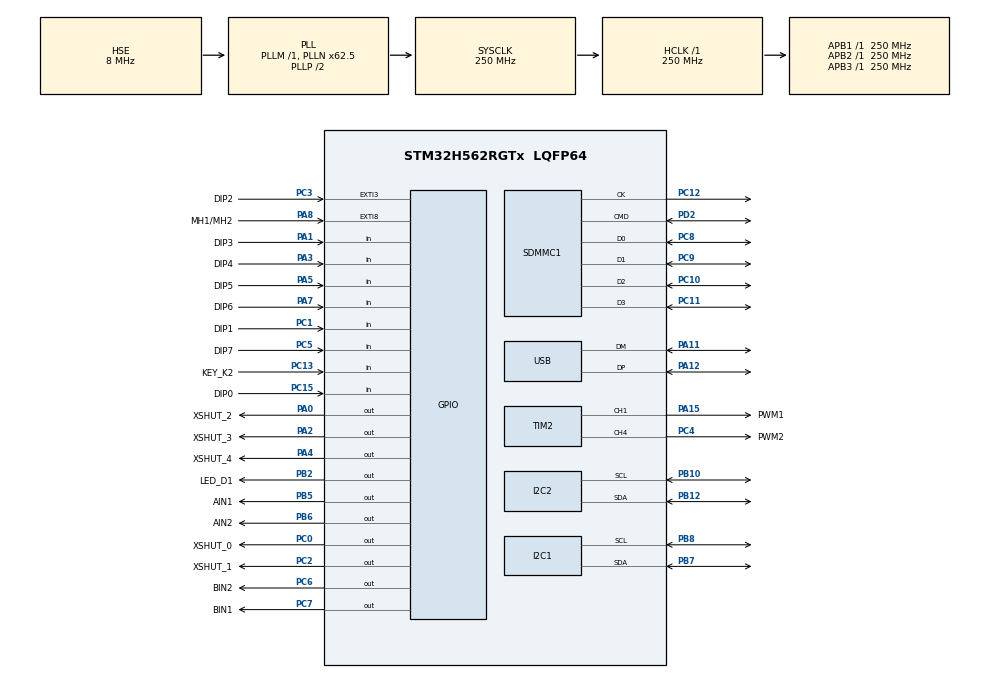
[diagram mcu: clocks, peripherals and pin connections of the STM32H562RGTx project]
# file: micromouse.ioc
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BOOTPATH.BootPathName=LEGACY
BOOTPATH.UserSelectedBootPath=LEGACY
CORTEX_M33_NS.userName=CORTEX_M33
I2C1.Timing=0x60808CD3
I2C2.Timing=0x60808CD3
Mcu.Family=STM32H5
Mcu.Name=STM32H562RGTx
Mcu.Package=LQFP64
NVIC.PriorityGroup=NVIC_PRIORITYGROUP_4
PA0.GPIO_Label=XSHUT_2
PA0.Signal=GPIO_Output
PA1.GPIO_Label=DIP3
PA1.Signal=GPIO_Input
PA11.Mode=Device
PA11.Signal=USB_DM
PA12.Mode=Device
PA12.Signal=USB_DP
PA13(JTMS/SWDIO).Mode=Trace_Asynchronous_SW
PA13(JTMS/SWDIO).Signal=DEBUG_JTMS-SWDIO
PA14(JTCK/SWCLK).Mode=Trace_Asynchronous_SW
PA14(JTCK/SWCLK).Signal=DEBUG_JTCK-SWCLK
PA15(JTDI).GPIO_Label=PWM1
PA15(JTDI).Signal=S_TIM2_CH1
PA2.GPIO_Label=XSHUT_3
PA2.Signal=GPIO_Output
PA3.GPIO_Label=DIP4
PA3.Signal=GPIO_Input
PA4.GPIO_Label=XSHUT_4
PA4.Signal=GPIO_Output
PA5.GPIO_Label=DIP5
PA5.Signal=GPIO_Input
PA7.GPIO_Label=DIP6
PA7.Signal=GPIO_Input
PA8.GPIO_Label=MH1/MH2
PA8.Signal=GPXTI8
PB10.Mode=I2C
PB10.Signal=I2C2_SCL
PB12.Mode=I2C
PB12.Signal=I2C2_SDA
PB2.GPIO_Label=LED_D1
PB2.Signal=GPIO_Output
PB3(JTDO/TRACESWO).Mode=Trace_Asynchronous_SW
PB3(JTDO/TRACESWO).Signal=DEBUG_JTDO-SWO
PB5.GPIO_Label=AIN1
PB5.Signal=GPIO_Output
PB6.GPIO_Label=AIN2
PB6.Signal=GPIO_Output
PB7.Mode=I2C
PB7.Signal=I2C1_SDA
PB8.Mode=I2C
PB8.Signal=I2C1_SCL
PC0.GPIO_Label=XSHUT_0
PC0.Signal=GPIO_Output
PC1.GPIO_Label=DIP1
PC1.Signal=GPIO_Input
PC10.Mode=SD_4_bits_Wide_bus
PC10.Signal=SDMMC1_D2
PC11.Mode=SD_4_bits_Wide_bus
PC11.Signal=SDMMC1_D3
PC12.Mode=SD_4_bits_Wide_bus
PC12.Signal=SDMMC1_CK
PC13.GPIO_Label=KEY_K2
PC13.Signal=GPIO_Input
PC15-OSC32_OUT(OSC32_OUT).GPIO_Label=DIP0
PC15-OSC32_OUT(OSC32_OUT).Signal=GPIO_Input
PC2.GPIO_Label=XSHUT_1
PC2.Signal=GPIO_Output
PC3.GPIO_Label=DIP2
PC3.Signal=GPXTI3
PC4.GPIO_Label=PWM2
PC4.Signal=S_TIM2_CH4
PC5.GPIO_Label=DIP7
PC5.Signal=GPIO_Input
PC6.GPIO_Label=BIN2
PC6.Signal=GPIO_Output
PC7.GPIO_Label=BIN1
PC7.Signal=GPIO_Output
PC8.Mode=SD_4_bits_Wide_bus
PC8.Signal=SDMMC1_D0
PC9.Mode=SD_4_bits_Wide_bus
PC9.Signal=SDMMC1_D1
PD2.Mode=SD_4_bits_Wide_bus
PD2.Signal=SDMMC1_CMD
PH0-OSC_IN(PH0).Mode=HSE-External-Oscillator
PH0-OSC_IN(PH0).Signal=RCC_OSC_IN
PH1-OSC_OUT(PH1).Mode=HSE-External-Oscillator
PH1-OSC_OUT(PH1).Signal=RCC_OSC_OUT
ProjectManager.HeapSize=0x200
ProjectManager.StackSize=0x400
ProjectManager.TargetToolchain=STM32CubeIDE
RCC.ADCFreq_Value=250000000
RCC.AHBFreq_Value=250000000
RCC.APB1Freq_Value=250000000
RCC.APB1TimFreq_Value=250000000
RCC.APB2Freq_Value=250000000
RCC.APB2TimFreq_Value=250000000
RCC.APB3Freq_Value=250000000
RCC.CSI_VALUE=4000000
RCC.CortexFreq_Value=250000000
RCC.EPOD_VALUE=8000000
RCC.HCLKFreq_Value=250000000
RCC.HSE_VALUE=8000000
RCC.HSI48_VALUE=48000000
RCC.HSI_VALUE=64000000
RCC.LSE_VALUE=32768
RCC.LSIRC_VALUE=32000
RCC.PLLFRACN=4096
RCC.PLLN=62
RCC.PLLSourceVirtual=RCC_PLL1_SOURCE_HSE
RCC.SYSCLKFreq_VALUE=250000000
RCC.SYSCLKSource=RCC_SYSCLKSOURCE_PLLCLK
RCC.USBFreq_Value=48000000
RCC.VCOOutputFreq_Value=500000000
SH.S_TIM2_CH1.0=TIM2_CH1,PWM Generation1 CH1
SH.S_TIM2_CH4.0=TIM2_CH4,PWM Generation4 CH4
TIM2.Channel-PWM\ Generation1\ CH1=TIM_CHANNEL_1
TIM2.Channel-PWM\ Generation4\ CH4=TIM_CHANNEL_4
USB.VirtualMode=Device_Only
VP_BOOTPATH_VS_BOOTPATH.Mode=BP_Activate
VP_CORTEX_M33_NS_VS_Hclk.Mode=Hclk_Mode
VP_ICACHE_VS_ICACHE.Mode=DirectMappedCache
VP_MEMORYMAP_VS_MEMORYMAP.Mode=CurAppReg
VP_PWR_VS_LPOM.Mode=PowerOptimisation
VP_PWR_VS_SECSignals.Mode=Security/Privilege
VP_TIM2_VS_ClockSourceINT.Mode=Internal
board=custom

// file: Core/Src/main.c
/* USER CODE BEGIN Header */
/**
  ******************************************************************************
  * @file           : main.c
  * @brief          : Main program body
  ******************************************************************************
  * @attention
  *
  * Copyright (c) 2025 STMicroelectronics.
  * All rights reserved.
  *
  * This software is licensed under terms that can be found in the LICENSE file
  * in the root directory of this software component.
  * If no LICENSE file comes with this software, it is provided AS-IS.
  *
  ******************************************************************************
  */
/* USER CODE END Header */
#include "main.h"

/* USER CODE BEGIN Includes */
#include <stdio.h>
#include "solver.h"
//#include "API.h"
/* USER CODE END Includes */

I2C_HandleTypeDef hi2c1;
I2C_HandleTypeDef hi2c2;

SD_HandleTypeDef hsd1;

TIM_HandleTypeDef htim2;

PCD_HandleTypeDef hpcd_USB_DRD_FS;

void SystemClock_Config(void);
static void MX_GPIO_Init(void);
static void MX_ICACHE_Init(void);
static void MX_TIM2_Init(void);
static void MX_I2C1_Init(void);
static void MX_I2C2_Init(void);
static void MX_SDMMC1_SD_Init(void);
static void MX_USB_PCD_Init(void);

int main(int argc, char* argv[])
{

  /* MCU Configuration--------------------------------------------------------*/

  /* Reset of all peripherals, Initializes the Flash interface and the Systick. */
  HAL_Init();

  /* Configure the system clock */
  SystemClock_Config();

  /* Initialize all configured peripherals */
  MX_GPIO_Init();
  MX_ICACHE_Init();
  MX_TIM2_Init();
  MX_I2C1_Init();
  MX_I2C2_Init();
  MX_SDMMC1_SD_Init();
  MX_USB_PCD_Init();
  /* USER CODE BEGIN 2 */
  //debug_log("Running...");
  generateInitialWalls();
  /* USER CODE END 2 */

  /* Infinite loop */
  while (1)
  {
	  Action nextMove = solver();
  }
}

void SystemClock_Config(void)
{
  RCC_OscInitTypeDef RCC_OscInitStruct = {0};
  RCC_ClkInitTypeDef RCC_ClkInitStruct = {0};

  /** Configure the main internal regulator output voltage
  */
  __HAL_PWR_VOLTAGESCALING_CONFIG(PWR_REGULATOR_VOLTAGE_SCALE0);

  while(!__HAL_PWR_GET_FLAG(PWR_FLAG_VOSRDY)) {}

  /** Initializes the RCC Oscillators according to the specified parameters
  * in the RCC_OscInitTypeDef structure.
  */
  RCC_OscInitStruct.OscillatorType = RCC_OSCILLATORTYPE_HSI48|RCC_OSCILLATORTYPE_HSE;
  RCC_OscInitStruct.HSEState = RCC_HSE_ON;
  RCC_OscInitStruct.HSI48State = RCC_HSI48_ON;
  RCC_OscInitStruct.PLL.PLLState = RCC_PLL_ON;
  RCC_OscInitStruct.PLL.PLLSource = RCC_PLL1_SOURCE_HSE;
  RCC_OscInitStruct.PLL.PLLM = 1;
  RCC_OscInitStruct.PLL.PLLN = 62;
  RCC_OscInitStruct.PLL.PLLP = 2;
  RCC_OscInitStruct.PLL.PLLQ = 2;
  RCC_OscInitStruct.PLL.PLLR = 2;
  RCC_OscInitStruct.PLL.PLLRGE = RCC_PLL1_VCIRANGE_3;
  RCC_OscInitStruct.PLL.PLLVCOSEL = RCC_PLL1_VCORANGE_WIDE;
  RCC_OscInitStruct.PLL.PLLFRACN = 4096;
  if (HAL_RCC_OscConfig(&RCC_OscInitStruct) != HAL_OK)
  {
    Error_Handler();
  }

  /** Initializes the CPU, AHB and APB buses clocks
  */
  RCC_ClkInitStruct.ClockType = RCC_CLOCKTYPE_HCLK|RCC_CLOCKTYPE_SYSCLK
                              |RCC_CLOCKTYPE_PCLK1|RCC_CLOCKTYPE_PCLK2
                              |RCC_CLOCKTYPE_PCLK3;
  RCC_ClkInitStruct.SYSCLKSource = RCC_SYSCLKSOURCE_PLLCLK;
  RCC_ClkInitStruct.AHBCLKDivider = RCC_SYSCLK_DIV1;
  RCC_ClkInitStruct.APB1CLKDivider = RCC_HCLK_DIV1;
  RCC_ClkInitStruct.APB2CLKDivider = RCC_HCLK_DIV1;
  RCC_ClkInitStruct.APB3CLKDivider = RCC_HCLK_DIV1;

  if (HAL_RCC_ClockConfig(&RCC_ClkInitStruct, FLASH_LATENCY_5) != HAL_OK)
  {
    Error_Handler();
  }

  /** Configure the programming delay
  */
  __HAL_FLASH_SET_PROGRAM_DELAY(FLASH_PROGRAMMING_DELAY_2);
}

static void MX_I2C1_Init(void)
{

  hi2c1.Instance = I2C1;
  hi2c1.Init.Timing = 0x60808CD3;
  hi2c1.Init.OwnAddress1 = 0;
  hi2c1.Init.AddressingMode = I2C_ADDRESSINGMODE_7BIT;
  hi2c1.Init.DualAddressMode = I2C_DUALADDRESS_DISABLE;
  hi2c1.Init.OwnAddress2 = 0;
  hi2c1.Init.OwnAddress2Masks = I2C_OA2_NOMASK;
  hi2c1.Init.GeneralCallMode = I2C_GENERALCALL_DISABLE;
  hi2c1.Init.NoStretchMode = I2C_NOSTRETCH_DISABLE;
  if (HAL_I2C_Init(&hi2c1) != HAL_OK)
  {
    Error_Handler();
  }

  /** Configure Analogue filter
  */
  if (HAL_I2CEx_ConfigAnalogFilter(&hi2c1, I2C_ANALOGFILTER_ENABLE) != HAL_OK)
  {
    Error_Handler();
  }

  /** Configure Digital filter
  */
  if (HAL_I2CEx_ConfigDigitalFilter(&hi2c1, 0) != HAL_OK)
  {
    Error_Handler();
  }

}

static void MX_I2C2_Init(void)
{

  hi2c2.Instance = I2C2;
  hi2c2.Init.Timing = 0x60808CD3;
  hi2c2.Init.OwnAddress1 = 0;
  hi2c2.Init.AddressingMode = I2C_ADDRESSINGMODE_7BIT;
  hi2c2.Init.DualAddressMode = I2C_DUALADDRESS_DISABLE;
  hi2c2.Init.OwnAddress2 = 0;
  hi2c2.Init.OwnAddress2Masks = I2C_OA2_NOMASK;
  hi2c2.Init.GeneralCallMode = I2C_GENERALCALL_DISABLE;
  hi2c2.Init.NoStretchMode = I2C_NOSTRETCH_DISABLE;
  if (HAL_I2C_Init(&hi2c2) != HAL_OK)
  {
    Error_Handler();
  }

  /** Configure Analogue filter
  */
  if (HAL_I2CEx_ConfigAnalogFilter(&hi2c2, I2C_ANALOGFILTER_ENABLE) != HAL_OK)
  {
    Error_Handler();
  }

  /** Configure Digital filter
  */
  if (HAL_I2CEx_ConfigDigitalFilter(&hi2c2, 0) != HAL_OK)
  {
    Error_Handler();
  }

}

static void MX_ICACHE_Init(void)
{

  /** Enable instruction cache in 1-way (direct mapped cache)
  */
  if (HAL_ICACHE_ConfigAssociativityMode(ICACHE_1WAY) != HAL_OK)
  {
    Error_Handler();
  }
  if (HAL_ICACHE_Enable() != HAL_OK)
  {
    Error_Handler();
  }

}

static void MX_SDMMC1_SD_Init(void)
{

  hsd1.Instance = SDMMC1;
  hsd1.Init.ClockEdge = SDMMC_CLOCK_EDGE_RISING;
  hsd1.Init.ClockPowerSave = SDMMC_CLOCK_POWER_SAVE_DISABLE;
  hsd1.Init.BusWide = SDMMC_BUS_WIDE_4B;
  hsd1.Init.HardwareFlowControl = SDMMC_HARDWARE_FLOW_CONTROL_DISABLE;
  hsd1.Init.ClockDiv = 0;
  if (HAL_SD_Init(&hsd1) != HAL_OK)
  {
    Error_Handler();
  }

}

static void MX_TIM2_Init(void)
{

  TIM_ClockConfigTypeDef sClockSourceConfig = {0};
  TIM_MasterConfigTypeDef sMasterConfig = {0};
  TIM_OC_InitTypeDef sConfigOC = {0};

  htim2.Instance = TIM2;
  htim2.Init.Prescaler = 0;
  htim2.Init.CounterMode = TIM_COUNTERMODE_UP;
  htim2.Init.Period = 4294967295;
  htim2.Init.ClockDivision = TIM_CLOCKDIVISION_DIV1;
  htim2.Init.AutoReloadPreload = TIM_AUTORELOAD_PRELOAD_DISABLE;
  if (HAL_TIM_Base_Init(&htim2) != HAL_OK)
  {
    Error_Handler();
  }
  sClockSourceConfig.ClockSource = TIM_CLOCKSOURCE_INTERNAL;
  if (HAL_TIM_ConfigClockSource(&htim2, &sClockSourceConfig) != HAL_OK)
  {
    Error_Handler();
  }
  if (HAL_TIM_PWM_Init(&htim2) != HAL_OK)
  {
    Error_Handler();
  }
  sMasterConfig.MasterOutputTrigger = TIM_TRGO_RESET;
  sMasterConfig.MasterSlaveMode = TIM_MASTERSLAVEMODE_DISABLE;
  if (HAL_TIMEx_MasterConfigSynchronization(&htim2, &sMasterConfig) != HAL_OK)
  {
    Error_Handler();
  }
  sConfigOC.OCMode = TIM_OCMODE_PWM1;
  sConfigOC.Pulse = 0;
  sConfigOC.OCPolarity = TIM_OCPOLARITY_HIGH;
  sConfigOC.OCFastMode = TIM_OCFAST_DISABLE;
  if (HAL_TIM_PWM_ConfigChannel(&htim2, &sConfigOC, TIM_CHANNEL_1) != HAL_OK)
  {
    Error_Handler();
  }
  if (HAL_TIM_PWM_ConfigChannel(&htim2, &sConfigOC, TIM_CHANNEL_4) != HAL_OK)
  {
    Error_Handler();
  }
  HAL_TIM_MspPostInit(&htim2);

}

static void MX_USB_PCD_Init(void)
{

  hpcd_USB_DRD_FS.Instance = USB_DRD_FS;
  hpcd_USB_DRD_FS.Init.dev_endpoints = 8;
  hpcd_USB_DRD_FS.Init.speed = USBD_FS_SPEED;
  hpcd_USB_DRD_FS.Init.phy_itface = PCD_PHY_EMBEDDED;
  hpcd_USB_DRD_FS.Init.Sof_enable = DISABLE;
  hpcd_USB_DRD_FS.Init.low_power_enable = DISABLE;
  hpcd_USB_DRD_FS.Init.lpm_enable = DISABLE;
  hpcd_USB_DRD_FS.Init.battery_charging_enable = DISABLE;
  hpcd_USB_DRD_FS.Init.vbus_sensing_enable = DISABLE;
  hpcd_USB_DRD_FS.Init.bulk_doublebuffer_enable = DISABLE;
  hpcd_USB_DRD_FS.Init.iso_singlebuffer_enable = DISABLE;
  if (HAL_PCD_Init(&hpcd_USB_DRD_FS) != HAL_OK)
  {
    Error_Handler();
  }

}

static void MX_GPIO_Init(void)
{
  GPIO_InitTypeDef GPIO_InitStruct = {0};

  /* GPIO Ports Clock Enable */
  __HAL_RCC_GPIOC_CLK_ENABLE();
  __HAL_RCC_GPIOH_CLK_ENABLE();
  __HAL_RCC_GPIOA_CLK_ENABLE();
  __HAL_RCC_GPIOB_CLK_ENABLE();
  __HAL_RCC_GPIOD_CLK_ENABLE();

  /*Configure GPIO pin Output Level */
  HAL_GPIO_WritePin(GPIOC, XSHUT_0_Pin|XSHUT_1_Pin|BIN2_Pin|BIN1_Pin, GPIO_PIN_RESET);

  /*Configure GPIO pin Output Level */
  HAL_GPIO_WritePin(GPIOA, XSHUT_2_Pin|XSHUT_3_Pin|XSHUT_4_Pin, GPIO_PIN_RESET);

  /*Configure GPIO pin Output Level */
  HAL_GPIO_WritePin(GPIOB, LED_D1_Pin|AIN1_Pin|AIN2_Pin, GPIO_PIN_RESET);

  /*Configure GPIO pins : KEY_K2_Pin DIP0_Pin DIP1_Pin DIP7_Pin */
  GPIO_InitStruct.Pin = KEY_K2_Pin|DIP0_Pin|DIP1_Pin|DIP7_Pin;
  GPIO_InitStruct.Mode = GPIO_MODE_INPUT;
  GPIO_InitStruct.Pull = GPIO_NOPULL;
  HAL_GPIO_Init(GPIOC, &GPIO_InitStruct);

  /*Configure GPIO pins : XSHUT_0_Pin XSHUT_1_Pin BIN2_Pin BIN1_Pin */
  GPIO_InitStruct.Pin = XSHUT_0_Pin|XSHUT_1_Pin|BIN2_Pin|BIN1_Pin;
  GPIO_InitStruct.Mode = GPIO_MODE_OUTPUT_PP;
  GPIO_InitStruct.Pull = GPIO_NOPULL;
  GPIO_InitStruct.Speed = GPIO_SPEED_FREQ_LOW;
  HAL_GPIO_Init(GPIOC, &GPIO_InitStruct);

  /*Configure GPIO pin : DIP2_Pin */
  GPIO_InitStruct.Pin = DIP2_Pin;
  GPIO_InitStruct.Mode = GPIO_MODE_IT_RISING;
  GPIO_InitStruct.Pull = GPIO_NOPULL;
  HAL_GPIO_Init(DIP2_GPIO_Port, &GPIO_InitStruct);

  /*Configure GPIO pins : XSHUT_2_Pin XSHUT_3_Pin XSHUT_4_Pin */
  GPIO_InitStruct.Pin = XSHUT_2_Pin|XSHUT_3_Pin|XSHUT_4_Pin;
  GPIO_InitStruct.Mode = GPIO_MODE_OUTPUT_PP;
  GPIO_InitStruct.Pull = GPIO_NOPULL;
  GPIO_InitStruct.Speed = GPIO_SPEED_FREQ_LOW;
  HAL_GPIO_Init(GPIOA, &GPIO_InitStruct);

  /*Configure GPIO pins : DIP3_Pin DIP4_Pin DIP5_Pin DIP6_Pin */
  GPIO_InitStruct.Pin = DIP3_Pin|DIP4_Pin|DIP5_Pin|DIP6_Pin;
  GPIO_InitStruct.Mode = GPIO_MODE_INPUT;
  GPIO_InitStruct.Pull = GPIO_NOPULL;
  HAL_GPIO_Init(GPIOA, &GPIO_InitStruct);

  /*Configure GPIO pins : LED_D1_Pin AIN1_Pin AIN2_Pin */
  GPIO_InitStruct.Pin = LED_D1_Pin|AIN1_Pin|AIN2_Pin;
  GPIO_InitStruct.Mode = GPIO_MODE_OUTPUT_PP;
  GPIO_InitStruct.Pull = GPIO_NOPULL;
  GPIO_InitStruct.Speed = GPIO_SPEED_FREQ_LOW;
  HAL_GPIO_Init(GPIOB, &GPIO_InitStruct);

  /*Configure GPIO pin : MH1_MH2_Pin */
  GPIO_InitStruct.Pin = MH1_MH2_Pin;
  GPIO_InitStruct.Mode = GPIO_MODE_IT_RISING;
  GPIO_InitStruct.Pull = GPIO_NOPULL;
  HAL_GPIO_Init(MH1_MH2_GPIO_Port, &GPIO_InitStruct);

}

void Error_Handler(void)
{
  __disable_irq();
  while (1)
  {
  }
}
